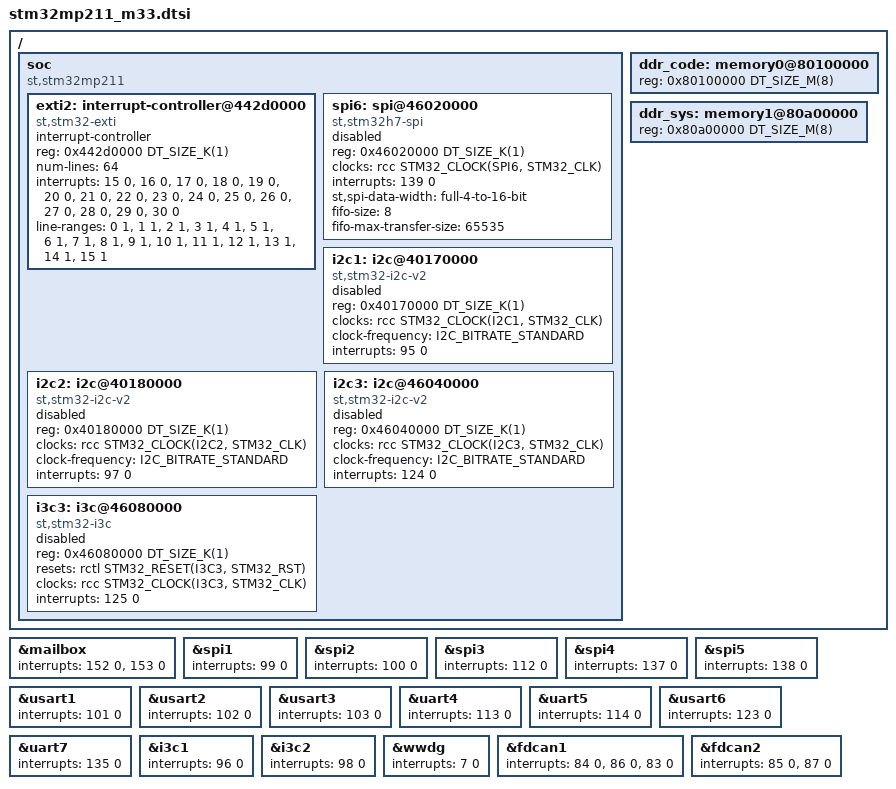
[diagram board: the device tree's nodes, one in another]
/*
 * Copyright (C) 2026 STMicroelectronics
 *
 * SPDX-License-Identifier: Apache-2.0
 */

#include <st/mp2/stm32mp2_m33.dtsi>

/ {
	soc {
		compatible = "st,stm32mp211", "st,stm32mp2", "simple-bus";

		exti2: interrupt-controller@442d0000 {
			compatible = "st,stm32-exti";
			interrupt-controller;
			#interrupt-cells = <1>;
			#address-cells = <0>;
			reg = <0x442d0000 DT_SIZE_K(1)>;
			num-lines = <64>;
			interrupts = <15 0>, <16 0>, <17 0>, <18 0>,
				     <19 0>, <20 0>, <21 0>, <22 0>,
				     <23 0>, <24 0>, <25 0>, <26 0>,
				     <27 0>, <28 0>, <29 0>, <30 0>;
			interrupt-names = "line0", "line1", "line2", "line3",
					  "line4", "line5", "line6", "line7",
					  "line8", "line9", "line10", "line11",
					  "line12", "line13", "line14", "line15";
			line-ranges = <0 1>, <1 1>, <2 1>, <3 1>,
				      <4 1>, <5 1>, <6 1>, <7 1>,
				      <8 1>, <9 1>, <10 1>, <11 1>,
				      <12 1>, <13 1>, <14 1>, <15 1>;
		};

		spi6: spi@46020000 {
			compatible = "st,stm32h7-spi", "st,stm32-spi-fifo", "st,stm32-spi";
			reg = <0x46020000 DT_SIZE_K(1)>;
			#address-cells = <1>;
			#size-cells = <0>;
			clocks = <&rcc STM32_CLOCK(SPI6, STM32_CLK)>;
			interrupts = <139 0>;
			st,spi-data-width = "full-4-to-16-bit";
			fifo-size = <8>;
			fifo-max-transfer-size = <65535>;
			status = "disabled";
		};

		i2c1: i2c@40170000 {
			compatible = "st,stm32-i2c-v2";
			reg = <0x40170000 DT_SIZE_K(1)>;
			#address-cells = <1>;
			#size-cells = <0>;
			clocks = <&rcc STM32_CLOCK(I2C1, STM32_CLK)>;
			clock-frequency = <I2C_BITRATE_STANDARD>;
			interrupts = <95 0>;
			interrupt-names = "combined";
			status = "disabled";
		};

		i2c2: i2c@40180000 {
			compatible = "st,stm32-i2c-v2";
			reg = <0x40180000 DT_SIZE_K(1)>;
			#address-cells = <1>;
			#size-cells = <0>;
			clocks = <&rcc STM32_CLOCK(I2C2, STM32_CLK)>;
			clock-frequency = <I2C_BITRATE_STANDARD>;
			interrupts = <97 0>;
			interrupt-names = "combined";
			status = "disabled";
		};

		i2c3: i2c@46040000 {
			compatible = "st,stm32-i2c-v2";
			reg = <0x46040000 DT_SIZE_K(1)>;
			#address-cells = <1>;
			#size-cells = <0>;
			clocks = <&rcc STM32_CLOCK(I2C3, STM32_CLK)>;
			clock-frequency = <I2C_BITRATE_STANDARD>;
			interrupts = <124 0>;
			interrupt-names = "combined";
			status = "disabled";
		};

		i3c3: i3c@46080000 {
			compatible = "st,stm32-i3c";
			reg = <0x46080000 DT_SIZE_K(1)>;
			#address-cells = <3>;
			#size-cells = <0>;
			resets = <&rctl STM32_RESET(I3C3, STM32_RST)>;
			clocks = <&rcc STM32_CLOCK(I3C3, STM32_CLK)>;
			interrupts = <125 0>;
			interrupt-names = "combined";
			status = "disabled";
		};
	};

	ddr_code: memory0@80100000 {
		reg = <0x80100000 DT_SIZE_M(8)>;
		ranges = <0x0 0x80100000 DT_SIZE_M(8)>;
		#address-cells = <1>;
		#size-cells = <1>;
	};

	ddr_sys: memory1@80a00000 {
		reg = <0x80a00000 DT_SIZE_M(8)>;
		ranges = <0x0 0x80a00000 DT_SIZE_M(8)>;
		#address-cells = <1>;
		#size-cells = <1>;
	};
};

&mailbox {
	interrupts = <152 0>, <153 0>;
	interrupt-names = "rxo", "txf";
};

&spi1 {
	interrupts = <99 0>;
};

&spi2 {
	interrupts = <100 0>;
};

&spi3 {
	interrupts = <112 0>;
};

&spi4 {
	interrupts = <137 0>;
};

&spi5 {
	interrupts = <138 0>;
};

&usart1 {
	interrupts = <101 0>;
};

&usart2 {
	interrupts = <102 0>;
};

&usart3 {
	interrupts = <103 0>;
};

&uart4 {
	interrupts = <113 0>;
};

&uart5 {
	interrupts = <114 0>;
};

&usart6 {
	interrupts = <123 0>;
};

&uart7 {
	interrupts = <135 0>;
};

&i2c2 {
	interrupts = <97 0>;
};

&i2c3 {
	interrupts = <124 0>;
};

&i3c1 {
	interrupts = <96 0>;
};

&i3c2 {
	interrupts = <98 0>;
};

&wwdg {
	interrupts = <7 0>;
};

&fdcan1 {
	interrupts = <84 0>, <86 0>, <83 0>;
	interrupt-names = "int0", "int1", "calib";
};

&fdcan2 {
	interrupts = <85 0>, <87 0>;
	interrupt-names = "int0", "int1";
};
